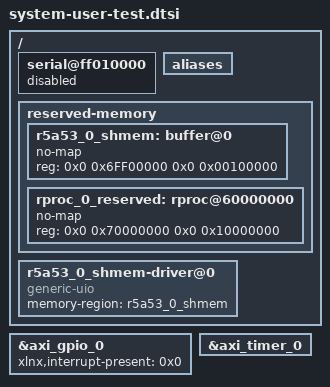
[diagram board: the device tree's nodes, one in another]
/include/ "system-conf.dtsi"
/ {

serial@ff010000 {
                status = "disabled";
                };

aliases {
                /delete-property/ serial1;
        };

/* RPU0 DDR */         
reserved-memory {
                #address-cells = <2>;
                #size-cells = <2>;
                ranges;
                
                r5a53_0_shmem: buffer@0 {
                          no-map;
                          reg = <0x0 0x6FF00000 0x0 0x00100000>;
                          };

                rproc_0_reserved: rproc@60000000 {
                          no-map;
                          reg = <0x0 0x70000000 0x0 0x10000000>;
                          };
                };

r5a53_0_shmem-driver@0 {
                       compatible = "generic-uio";
                       memory-region = <&r5a53_0_shmem>;
                       };

};


/delete-node/ &uart1;

&axi_gpio_0 {
            /delete-property/ interrupt-controller ;
            /delete-property/ interrupt-names ;
            /delete-property/ interrupt-parent ;
            /delete-property/ interrupts ;
            xlnx,interrupt-present = <0x0>;
            };

&axi_timer_0 {
             /delete-property/ interrupt-names ;
             /delete-property/ interrupt-parent ;
             /delete-property/ interrupts ;
             };
